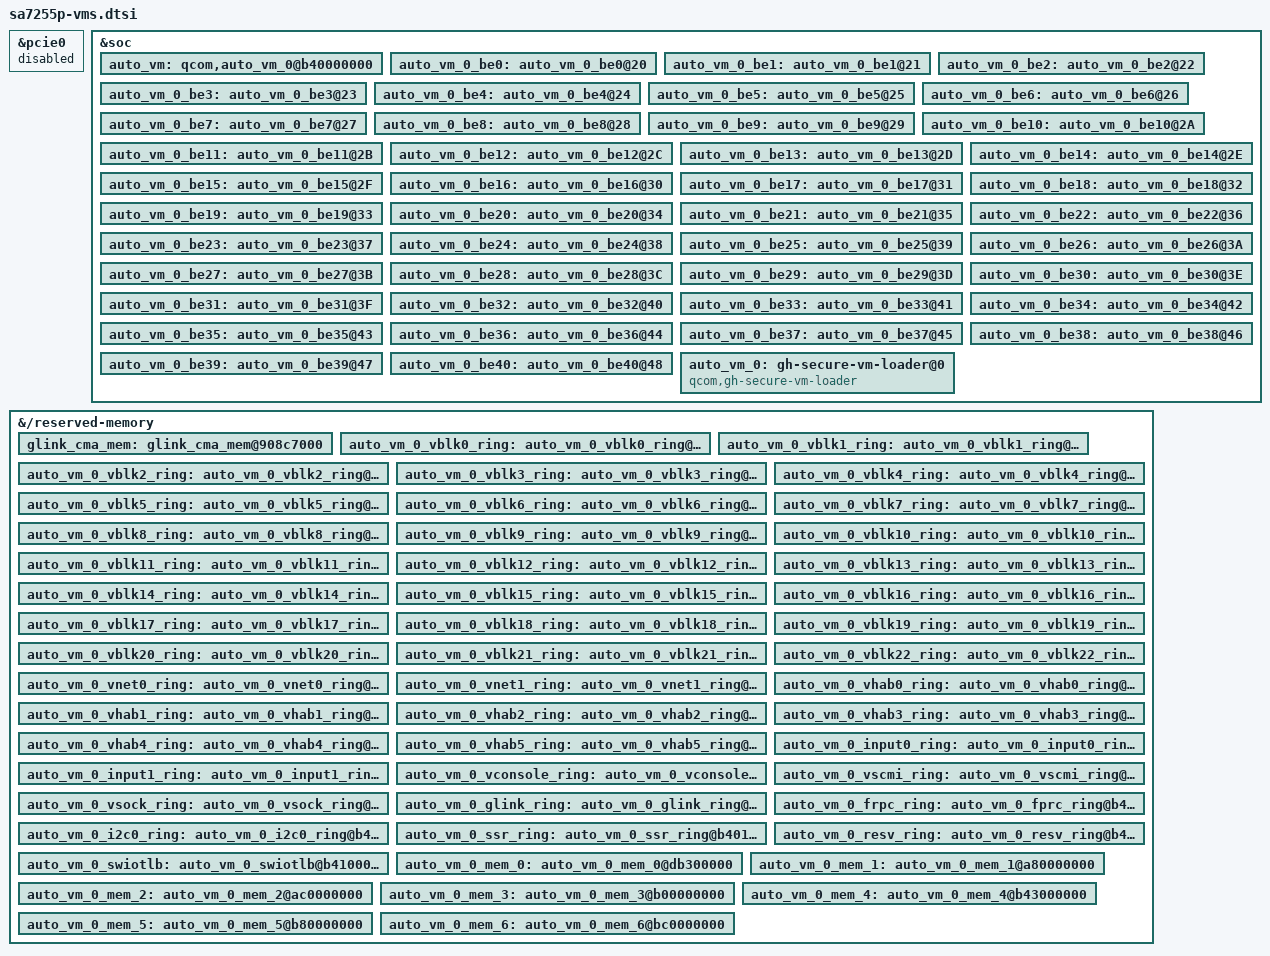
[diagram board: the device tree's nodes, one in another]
// SPDX-License-Identifier: BSD-3-Clause
/*
 * Copyright (c) Qualcomm Technologies, Inc. and/or its subsidiaries.
 */

#include <oot-dt-bindings/qcom-shmem.h>

&pcie0 {
	status = "disabled";
};

&soc {
	auto_vm: qcom,auto_vm_0@b40000000 {
		reg = <0xb 0x40000000 0x0 0x3000000>;
		vm_name = "autoghgvm";
		shared-buffers = <&auto_vm_0_vblk0_ring
				&auto_vm_0_vblk1_ring
				&auto_vm_0_vblk2_ring
				&auto_vm_0_vblk3_ring
				&auto_vm_0_vblk4_ring
				&auto_vm_0_vblk5_ring
				&auto_vm_0_vblk6_ring
				&auto_vm_0_vblk7_ring
				&auto_vm_0_vblk8_ring
				&auto_vm_0_vblk9_ring
				&auto_vm_0_vblk10_ring
				&auto_vm_0_vblk11_ring
				&auto_vm_0_vblk12_ring
				&auto_vm_0_vblk13_ring
				&auto_vm_0_vblk14_ring
				&auto_vm_0_vblk15_ring
				&auto_vm_0_vblk16_ring
				&auto_vm_0_vblk17_ring
				&auto_vm_0_vblk18_ring
				&auto_vm_0_vblk19_ring
				&auto_vm_0_vblk20_ring
				&auto_vm_0_vblk21_ring
				&auto_vm_0_vblk22_ring
				&auto_vm_0_vnet0_ring
				&auto_vm_0_vnet1_ring
				&auto_vm_0_vhab0_ring
				&auto_vm_0_vhab1_ring
				&auto_vm_0_vhab2_ring
				&auto_vm_0_vhab3_ring
				&auto_vm_0_vhab4_ring
				&auto_vm_0_vhab5_ring
				&auto_vm_0_input0_ring
				&auto_vm_0_input1_ring
				&auto_vm_0_vconsole_ring
				&auto_vm_0_vscmi_ring
				&auto_vm_0_vsock_ring
				&auto_vm_0_glink_ring
				&auto_vm_0_frpc_ring
				&auto_vm_0_i2c0_ring
				&auto_vm_0_ssr_ring
				&auto_vm_0_resv_ring
				&auto_vm_0_swiotlb>;
	};

	auto_vm_0_be0: auto_vm_0_be0@20 {
		qcom,vm = <&auto_vm>;
		qcom,label = <0x20>;
	};

	auto_vm_0_be1: auto_vm_0_be1@21 {
		qcom,vm = <&auto_vm>;
		qcom,label = <0x21>;
	};

	auto_vm_0_be2: auto_vm_0_be2@22 {
		qcom,vm = <&auto_vm>;
		qcom,label = <0x22>;
	};

	auto_vm_0_be3: auto_vm_0_be3@23 {
		qcom,vm = <&auto_vm>;
		qcom,label = <0x23>;
	};

	auto_vm_0_be4: auto_vm_0_be4@24 {
		qcom,vm = <&auto_vm>;
		qcom,label = <0x24>;
	};

	auto_vm_0_be5: auto_vm_0_be5@25 {
		qcom,vm = <&auto_vm>;
		qcom,label = <0x25>;
	};

	auto_vm_0_be6: auto_vm_0_be6@26 {
		qcom,vm = <&auto_vm>;
		qcom,label = <0x26>;
	};

	auto_vm_0_be7: auto_vm_0_be7@27 {
		qcom,vm = <&auto_vm>;
		qcom,label = <0x27>;
	};

	auto_vm_0_be8: auto_vm_0_be8@28 {
		qcom,vm = <&auto_vm>;
		qcom,label = <0x28>;
	};

	auto_vm_0_be9: auto_vm_0_be9@29 {
		qcom,vm = <&auto_vm>;
		qcom,label = <0x29>;
	};

	auto_vm_0_be10: auto_vm_0_be10@2A {
		qcom,vm = <&auto_vm>;
		qcom,label = <0x2A>;
	};

	auto_vm_0_be11: auto_vm_0_be11@2B {
		qcom,vm = <&auto_vm>;
		qcom,label = <0x2B>;
	};

	auto_vm_0_be12: auto_vm_0_be12@2C {
		qcom,vm = <&auto_vm>;
		qcom,label = <0x2C>;
	};

	auto_vm_0_be13: auto_vm_0_be13@2D {
		qcom,vm = <&auto_vm>;
		qcom,label = <0x2D>;
	};

	auto_vm_0_be14: auto_vm_0_be14@2E {
		qcom,vm = <&auto_vm>;
		qcom,label = <0x2E>;
	};

	auto_vm_0_be15: auto_vm_0_be15@2F {
		qcom,vm = <&auto_vm>;
		qcom,label = <0x2F>;
	};

	auto_vm_0_be16: auto_vm_0_be16@30 {
		qcom,vm = <&auto_vm>;
		qcom,label = <0x30>;
	};

	auto_vm_0_be17: auto_vm_0_be17@31 {
		qcom,vm = <&auto_vm>;
		qcom,label = <0x31>;
	};

	auto_vm_0_be18: auto_vm_0_be18@32 {
		qcom,vm = <&auto_vm>;
		qcom,label = <0x32>;
	};

	auto_vm_0_be19: auto_vm_0_be19@33 {
		qcom,vm = <&auto_vm>;
		qcom,label = <0x33>;
	};

	auto_vm_0_be20: auto_vm_0_be20@34 {
		qcom,vm = <&auto_vm>;
		qcom,label = <0x34>;
	};

	auto_vm_0_be21: auto_vm_0_be21@35 {
		qcom,vm = <&auto_vm>;
		qcom,label = <0x35>;
	};

	auto_vm_0_be22: auto_vm_0_be22@36 {
		qcom,vm = <&auto_vm>;
		qcom,label = <0x36>;
	};

	auto_vm_0_be23: auto_vm_0_be23@37 {
		qcom,vm = <&auto_vm>;
		qcom,label = <0x37>;
	};

	auto_vm_0_be24: auto_vm_0_be24@38 {
		qcom,vm = <&auto_vm>;
		qcom,label = <0x38>;
	};

	auto_vm_0_be25: auto_vm_0_be25@39 {
		qcom,vm = <&auto_vm>;
		qcom,label = <0x39>;
	};

	auto_vm_0_be26: auto_vm_0_be26@3A {
		qcom,vm = <&auto_vm>;
		qcom,label = <0x3A>;
	};

	auto_vm_0_be27: auto_vm_0_be27@3B {
		qcom,vm = <&auto_vm>;
		qcom,label = <0x3B>;
	};

	auto_vm_0_be28: auto_vm_0_be28@3C {
		qcom,vm = <&auto_vm>;
		qcom,label = <0x3C>;
	};

	auto_vm_0_be29: auto_vm_0_be29@3D {
		qcom,vm = <&auto_vm>;
		qcom,label = <0x3D>;
	};

	auto_vm_0_be30: auto_vm_0_be30@3E {
		qcom,vm = <&auto_vm>;
		qcom,label = <0x3E>;
	};

	auto_vm_0_be31: auto_vm_0_be31@3F {
		qcom,vm = <&auto_vm>;
		qcom,label = <0x3F>;
	};

	auto_vm_0_be32: auto_vm_0_be32@40 {
		qcom,vm = <&auto_vm>;
		qcom,label = <0x40>;
	};

	auto_vm_0_be33: auto_vm_0_be33@41 {
		qcom,vm = <&auto_vm>;
		qcom,label = <0x41>;
	};

	auto_vm_0_be34: auto_vm_0_be34@42 {
		qcom,vm = <&auto_vm>;
		qcom,label = <0x42>;
	};

	auto_vm_0_be35: auto_vm_0_be35@43 {
		qcom,vm = <&auto_vm>;
		qcom,label = <0x43>;
	};

	auto_vm_0_be36: auto_vm_0_be36@44 {
		qcom,vm = <&auto_vm>;
		qcom,label = <0x44>;
	};

	auto_vm_0_be37: auto_vm_0_be37@45 {
		qcom,vm = <&auto_vm>;
		qcom,label = <0x45>;
	};

	auto_vm_0_be38: auto_vm_0_be38@46 {
		qcom,vm = <&auto_vm>;
		qcom,label = <0x46>;
	};

	auto_vm_0_be39: auto_vm_0_be39@47 {
		qcom,vm = <&auto_vm>;
		qcom,label = <0x47>;
	};

	auto_vm_0_be40: auto_vm_0_be40@48 {
		qcom,vm = <&auto_vm>;
		qcom,label = <0x48>;
	};

	auto_vm_0: gh-secure-vm-loader@0 {
		compatible = "qcom,gh-secure-vm-loader";
		qcom,pas-id = <44>;
		qcom,vmid = <52>;
		qcom,firmware-name = "autoghgvm";
		qcom,firmware-index = <0>;
		memory-region = <&auto_vm_0_mem_0 &auto_vm_0_mem_1
				&auto_vm_0_mem_2 &auto_vm_0_mem_3
				&auto_vm_0_mem_4 &auto_vm_0_mem_5
				&auto_vm_0_mem_6>;
		shared-regions = <&glink_cma_mem>;
		enable-gvm-dump;
		virtio-backends = <&auto_vm_0_be0
				&auto_vm_0_be1
				&auto_vm_0_be2
				&auto_vm_0_be3
				&auto_vm_0_be4
				&auto_vm_0_be5
				&auto_vm_0_be6
				&auto_vm_0_be7
				&auto_vm_0_be8
				&auto_vm_0_be9
				&auto_vm_0_be10
				&auto_vm_0_be11
				&auto_vm_0_be12
				&auto_vm_0_be13
				&auto_vm_0_be14
				&auto_vm_0_be15
				&auto_vm_0_be16
				&auto_vm_0_be17
				&auto_vm_0_be18
				&auto_vm_0_be19
				&auto_vm_0_be20
				&auto_vm_0_be21
				&auto_vm_0_be22
				&auto_vm_0_be23
				&auto_vm_0_be24
				&auto_vm_0_be25
				&auto_vm_0_be26
				&auto_vm_0_be27
				&auto_vm_0_be28
				&auto_vm_0_be29
				&auto_vm_0_be30
				&auto_vm_0_be31
				&auto_vm_0_be32
				&auto_vm_0_be33
				&auto_vm_0_be34
				&auto_vm_0_be35
				&auto_vm_0_be36
				&auto_vm_0_be37
				&auto_vm_0_be38
				&auto_vm_0_be39
				&auto_vm_0_be40>;
	};
};

&{/reserved-memory} {
	#address-cells = <2>;
	#size-cells = <2>;
	ranges;

	glink_cma_mem: glink_cma_mem@908c7000 {
		no-map;
		reg = <0x0 0x908c7000 0x0 0x9000>;
		qcom,dst-vmids = <AC_VM_CDSP_Q6_ELF>;
		qcom,dst-perms = <QCOM_PERM_RWX>;
		gunyah-label = <0x60>;
	};

	auto_vm_0_vblk0_ring: auto_vm_0_vblk0_ring@b40000000 {
		no-map;
		reg = <0xb 0x40000000 0x0 0x4000>;
		gunyah-label = <0x20>;
	};

	auto_vm_0_vblk1_ring: auto_vm_0_vblk1_ring@b40004000 {
		no-map;
		reg = <0xb 0x40004000 0x0 0x4000>;
		gunyah-label = <0x21>;
	};

	auto_vm_0_vblk2_ring: auto_vm_0_vblk2_ring@b40008000 {
		no-map;
		reg = <0xb 0x40008000 0x0 0x4000>;
		gunyah-label = <0x22>;
	};

	auto_vm_0_vblk3_ring: auto_vm_0_vblk3_ring@b4000C000 {
		no-map;
		reg = <0xb 0x4000C000 0x0 0x4000>;
		gunyah-label = <0x23>;
	};

	auto_vm_0_vblk4_ring: auto_vm_0_vblk4_ring@b40010000 {
		no-map;
		reg = <0xb 0x40010000 0x0 0x4000>;
		gunyah-label = <0x24>;
	};

	auto_vm_0_vblk5_ring: auto_vm_0_vblk5_ring@b40014000 {
		no-map;
		reg = <0xb 0x40014000 0x0 0x4000>;
		gunyah-label = <0x25>;
	};

	auto_vm_0_vblk6_ring: auto_vm_0_vblk6_ring@b40018000 {
		no-map;
		reg = <0xb 0x40018000 0x0 0x4000>;
		gunyah-label = <0x26>;
	};

	auto_vm_0_vblk7_ring: auto_vm_0_vblk7_ring@b4001C000 {
		no-map;
		reg = <0xb 0x4001C000 0x0 0x4000>;
		gunyah-label = <0x27>;
	};

	auto_vm_0_vblk8_ring: auto_vm_0_vblk8_ring@b40020000 {
		no-map;
		reg = <0xb 0x40020000 0x0 0x4000>;
		gunyah-label = <0x28>;
	};

	auto_vm_0_vblk9_ring: auto_vm_0_vblk9_ring@b40024000 {
		no-map;
		reg = <0xb 0x40024000 0x0 0x4000>;
		gunyah-label = <0x29>;
	};

	auto_vm_0_vblk10_ring: auto_vm_0_vblk10_ring@b40028000 {
		no-map;
		reg = <0xb 0x40028000 0x0 0x4000>;
		gunyah-label = <0x2A>;
	};

	auto_vm_0_vblk11_ring: auto_vm_0_vblk11_ring@b4002C000 {
		no-map;
		reg = <0xb 0x4002C000 0x0 0x4000>;
		gunyah-label = <0x2B>;
	};

	auto_vm_0_vblk12_ring: auto_vm_0_vblk12_ring@b40030000 {
		no-map;
		reg = <0xb 0x40030000 0x0 0x4000>;
		gunyah-label = <0x2C>;
	};

	auto_vm_0_vblk13_ring: auto_vm_0_vblk13_ring@b40034000 {
		no-map;
		reg = <0xb 0x40034000 0x0 0x4000>;
		gunyah-label = <0x2D>;
	};

	auto_vm_0_vblk14_ring: auto_vm_0_vblk14_ring@b40038000 {
		no-map;
		reg = <0xb 0x40038000 0x0 0x4000>;
		gunyah-label = <0x2E>;
	};

	auto_vm_0_vblk15_ring: auto_vm_0_vblk15_ring@b4003C000 {
		no-map;
		reg = <0xb 0x4003C000 0x0 0x4000>;
		gunyah-label = <0x2F>;
	};

	auto_vm_0_vblk16_ring: auto_vm_0_vblk16_ring@b40040000 {
		no-map;
		reg = <0xb 0x40040000 0x0 0x4000>;
		gunyah-label = <0x30>;
	};

	auto_vm_0_vblk17_ring: auto_vm_0_vblk17_ring@b40044000 {
		no-map;
		reg = <0xb 0x40044000 0x0 0x4000>;
		gunyah-label = <0x31>;
	};

	auto_vm_0_vblk18_ring: auto_vm_0_vblk18_ring@b40048000 {
		no-map;
		reg = <0xb 0x40048000 0x0 0x4000>;
		gunyah-label = <0x32>;
	};

	auto_vm_0_vblk19_ring: auto_vm_0_vblk19_ring@b4004C000 {
		no-map;
		reg = <0xb 0x4004C000 0x0 0x4000>;
		gunyah-label = <0x33>;
	};

	auto_vm_0_vblk20_ring: auto_vm_0_vblk20_ring@b40050000 {
		no-map;
		reg = <0xb 0x40050000 0x0 0x4000>;
		gunyah-label = <0x34>;
	};

	auto_vm_0_vblk21_ring: auto_vm_0_vblk21_ring@b40054000 {
		no-map;
		reg = <0xb 0x40054000 0x0 0x4000>;
		gunyah-label = <0x35>;
	};

	auto_vm_0_vblk22_ring: auto_vm_0_vblk22_ring@b40058000 {
		no-map;
		reg = <0xb 0x40058000 0x0 0x4000>;
		gunyah-label = <0x36>;
	};

	auto_vm_0_vnet0_ring: auto_vm_0_vnet0_ring@b4005C000 {
		no-map;
		reg = <0xb 0x4005C000 0x0 0x8000>;
		gunyah-label = <0x37>;
	};

	auto_vm_0_vnet1_ring: auto_vm_0_vnet1_ring@b40064000 {
		no-map;
		reg = <0xb 0x40064000 0x0 0x8000>;
		gunyah-label = <0x38>;
	};

	auto_vm_0_vhab0_ring: auto_vm_0_vhab0_ring@b4006C000 {
		no-map;
		reg = <0xb 0x4006C000 0x0 0x10000>;
		gunyah-label = <0x39>;
	};

	auto_vm_0_vhab1_ring: auto_vm_0_vhab1_ring@b4007C000 {
		no-map;
		reg = <0xb 0x4007C000 0x0 0x10000>;
		gunyah-label = <0x3A>;
	};

	auto_vm_0_vhab2_ring: auto_vm_0_vhab2_ring@b4008C000 {
		no-map;
		reg = <0xb 0x4008C000 0x0 0x40000>;
		gunyah-label = <0x3B>;
	};

	auto_vm_0_vhab3_ring: auto_vm_0_vhab3_ring@b400CC000 {
		no-map;
		reg = <0xb 0x400CC000 0x0 0x50000>;
		gunyah-label = <0x3C>;
	};

	auto_vm_0_vhab4_ring: auto_vm_0_vhab4_ring@b4011C000 {
		no-map;
		reg = <0xb 0x4011C000 0x0 0x30000>;
		gunyah-label = <0x3D>;
	};

	auto_vm_0_vhab5_ring: auto_vm_0_vhab5_ring@b4014C000 {
		no-map;
		reg = <0xb 0x4014C000 0x0 0x30000>;
		gunyah-label = <0x3E>;
	};

	auto_vm_0_input0_ring: auto_vm_0_input0_ring@b4017C000 {
		no-map;
		reg = <0xb 0x4017C000 0x0 0x4000>;
		gunyah-label = <0x3F>;
	};

	auto_vm_0_input1_ring: auto_vm_0_input1_ring@b40180000 {
		no-map;
		reg = <0xb 0x40180000 0x0 0x4000>;
		gunyah-label = <0x40>;
	};

	auto_vm_0_vconsole_ring: auto_vm_0_vconsole_ring@b40184000 {
		no-map;
		reg = <0xb 0x40184000 0x0 0x8000>;
		gunyah-label = <0x41>;
	};

	auto_vm_0_vscmi_ring: auto_vm_0_vscmi_ring@b4018C000 {
		no-map;
		reg = <0xb 0x4018C000 0x0 0x8000>;
		gunyah-label = <0x42>;
	};

	auto_vm_0_vsock_ring: auto_vm_0_vsock_ring@b40194000 {
		no-map;
		reg = <0xb 0x40194000 0x0 0xC000>;
		gunyah-label = <0x43>;
	};

	auto_vm_0_glink_ring: auto_vm_0_glink_ring@b401A0000 {
		no-map;
		reg = <0xb 0x401A0000 0x0 0x2000>;
		gunyah-label = <0x44>;
	};

	auto_vm_0_frpc_ring: auto_vm_0_fprc_ring@b401A2000 {
		no-map;
		reg = <0xb 0x401A2000 0x0 0x4000>;
		gunyah-label = <0x45>;
	};

	auto_vm_0_i2c0_ring: auto_vm_0_i2c0_ring@b401A6000 {
		no-map;
		reg = <0xb 0x401A6000 0x0 0x2000>;
		gunyah-label = <0x46>;
	};

	auto_vm_0_ssr_ring: auto_vm_0_ssr_ring@b401A8000 {
		no-map;
		reg = <0xb 0x401A8000 0x0 0x2000>;
		gunyah-label = <0x47>;
	};

	auto_vm_0_resv_ring: auto_vm_0_resv_ring@b401AA000 {
		no-map;
		reg = <0xb 0x401AA000 0x0 0xE56000>;
		gunyah-label = <0x48>;
	};

	auto_vm_0_swiotlb: auto_vm_0_swiotlb@b41000000 {
		no-map;
		reg = <0xb 0x41000000 0x0 0x2000000>;
		gunyah-label = <0x50>;
	};

	auto_vm_0_mem_0: auto_vm_0_mem_0@db300000 {
		no-map;
		reg = <0x0 0xdb300000 0x0 0x19000000>;/*400M*/
	};

	auto_vm_0_mem_1: auto_vm_0_mem_1@a80000000 {
		no-map;
		reg = <0xa 0x80000000 0x0 0x40000000>;/*1G*/
	};

	auto_vm_0_mem_2: auto_vm_0_mem_2@ac0000000 {
		no-map;
		reg = <0xa 0xc0000000 0x0 0x40000000>;/*1G*/
	};

	auto_vm_0_mem_3: auto_vm_0_mem_3@b00000000 {
		no-map;
		reg = <0xb 0x00000000 0x0 0x40000000>;/*1G*/
	};

	auto_vm_0_mem_4: auto_vm_0_mem_4@b43000000 {
		no-map;
		reg = <0xb 0x43000000 0x0 0x3D000000>;/*976M*/
	};

	auto_vm_0_mem_5: auto_vm_0_mem_5@b80000000 {
		no-map;
		reg = <0xb 0x80000000 0x0 0x40000000>;/*1G*/
	};

	auto_vm_0_mem_6: auto_vm_0_mem_6@bc0000000 {
		no-map;
		reg = <0xb 0xc0000000 0x0 0x3EC00000>;/*1004M*/
	};
};
